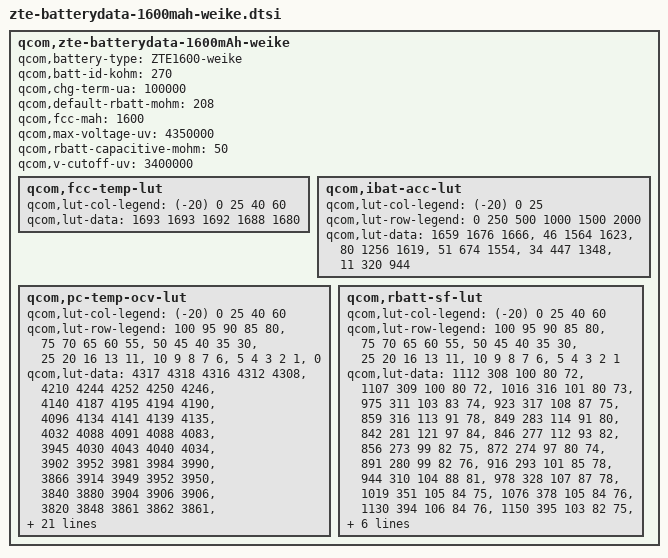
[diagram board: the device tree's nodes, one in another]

qcom,zte-batterydata-1600mAh-weike {
	qcom,battery-type = "ZTE1600-weike";
	qcom,batt-id-kohm = <270>;
	qcom,chg-term-ua = <100000>;
	qcom,default-rbatt-mohm = <208>;
	qcom,fcc-mah = <1600>;
	qcom,max-voltage-uv = <4350000>;
	qcom,rbatt-capacitive-mohm = <50>;
	qcom,v-cutoff-uv = <3400000>;

	qcom,fcc-temp-lut {
		qcom,lut-col-legend = <(-20) 0 25 40 60>;
		qcom,lut-data = <1693 1693 1692 1688 1680>;
	};

	qcom,ibat-acc-lut {
		qcom,lut-col-legend = <(-20) 0 25>;
		qcom,lut-row-legend = <0 250 500 1000 1500 2000>;
		qcom,lut-data = <1659 1676 1666>,
				<46 1564 1623>,
				<80 1256 1619>,
				<51 674 1554>,
				<34 447 1348>,
				<11 320 944>;
	};

	qcom,pc-temp-ocv-lut {
		qcom,lut-col-legend = <(-20) 0 25 40 60>;
		qcom,lut-row-legend = <100 95 90 85 80>,
					<75 70 65 60 55>,
					<50 45 40 35 30>,
					<25 20 16 13 11>,
					<10 9 8 7 6>,
					<5 4 3 2 1>,
					<0>;
		qcom,lut-data = <4317 4318 4316 4312 4308>,
				<4210 4244 4252 4250 4246>,
				<4140 4187 4195 4194 4190>,
				<4096 4134 4141 4139 4135>,
				<4032 4088 4091 4088 4083>,
				<3945 4030 4043 4040 4034>,
				<3902 3952 3981 3984 3990>,
				<3866 3914 3949 3952 3950>,
				<3840 3880 3904 3906 3906>,
				<3820 3848 3861 3862 3861>,
				<3805 3822 3832 3834 3832>,
				<3792 3802 3811 3812 3810>,
				<3778 3790 3794 3794 3793>,
				<3766 3780 3780 3780 3779>,
				<3753 3772 3770 3765 3756>,
				<3739 3760 3758 3748 3734>,
				<3724 3743 3739 3730 3716>,
				<3709 3722 3718 3708 3694>,
				<3696 3706 3696 3688 3675>,
				<3683 3697 3690 3683 3671>,
				<3675 3694 3689 3682 3670>,
				<3666 3692 3688 3681 3669>,
				<3655 3688 3686 3679 3668>,
				<3640 3685 3684 3676 3664>,
				<3621 3676 3674 3666 3650>,
				<3594 3654 3646 3636 3616>,
				<3557 3612 3600 3591 3570>,
				<3502 3554 3540 3529 3511>,
				<3422 3472 3458 3448 3428>,
				<3276 3347 3340 3329 3307>,
				<3024 3000 3040 3000 3000>;
	};

	qcom,rbatt-sf-lut {
		qcom,lut-col-legend = <(-20) 0 25 40 60>;
		qcom,lut-row-legend = <100 95 90 85 80>,
					<75 70 65 60 55>,
					<50 45 40 35 30>,
					<25 20 16 13 11>,
					<10 9 8 7 6>,
					<5 4 3 2 1>;
		qcom,lut-data = <1112 308 100 80 72>,
				<1107 309 100 80 72>,
				<1016 316 101 80 73>,
				<975 311 103 83 74>,
				<923 317 108 87 75>,
				<859 316 113 91 78>,
				<849 283 114 91 80>,
				<842 281 121 97 84>,
				<846 277 112 93 82>,
				<856 273 99 82 75>,
				<872 274 97 80 74>,
				<891 280 99 82 76>,
				<916 293 101 85 78>,
				<944 310 104 88 81>,
				<978 328 107 87 78>,
				<1019 351 105 84 75>,
				<1076 378 105 84 76>,
				<1130 394 106 84 76>,
				<1150 395 103 82 75>,
				<1234 420 105 83 75>,
				<1317 438 107 85 76>,
				<1425 458 110 87 78>,
				<1550 481 113 88 79>,
				<1728 509 118 90 80>,
				<1955 541 121 90 78>,
				<2269 571 119 88 78>,
				<2749 614 123 89 79>,
				<3541 683 131 93 81>,
				<5073 778 143 102 88>,
				<10146 1100 181 138 120>;
	};
};
